# STM32H7RSxx register map
File version: 0.2
CPU: CM7 r0p1, little endian, MPU, FPU, 4 interrupt priority bits
Registers are 32-bit, read-write, reset 0x0 unless marked. A register's access mark holds for its fields unless they carry their own. Offsets are from the block's base; [hi:lo] are bit positions; {n}, {i} and the like mark numbered series; 'fields as' and 'values as' point back to an identical list; <NAME> marks a mode.

## ETH (part 1 of 4) — Ethernet register block
Base 0x40028000
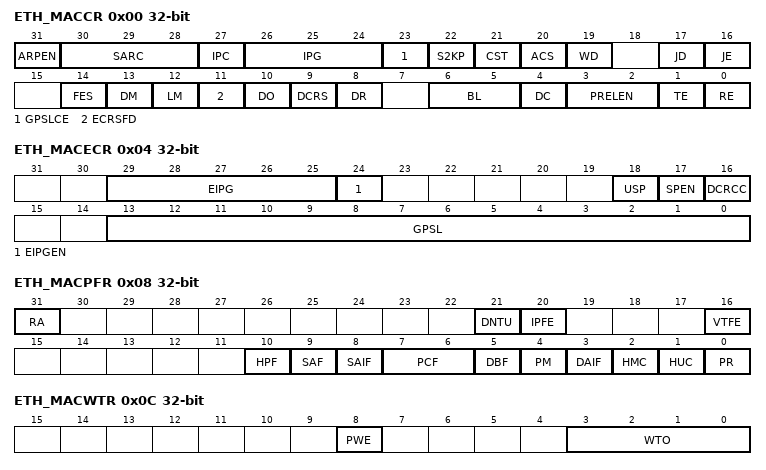
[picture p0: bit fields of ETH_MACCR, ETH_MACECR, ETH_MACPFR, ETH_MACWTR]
0x00 ETH_MACCR — Operating mode configuration register
  [31] ARPEN — ARP Offload Enable When this bit is set, the MAC can recognize an incoming ARP request packet and schedules the ARP packet for transmission. It forwards the ARP packet to the application and also indicate the events in the RxStatus. When this bit is reset, the MAC receiver does not recognize any ARP packet and indicates them as Type frame in the RxStatus.
  [30:28] SARC — Source Address Insertion or Replacement Control This field controls the source address insertion or replacement for all transmitted packets. Bit 30 specifies which MAC Address register (0 or 1) is used for source address insertion or replacement based on the values of Bits[29:28]: Others: Reserved, must not be used. Note: Changes to this field take effect only on the start of a packet. If you write to this register field when a packet is being transmitted, only the subsequent packet can use the updated value, that is, the current packet does not use the updated value.
    2=the MAC inserts the content of the MAC Address 0 registers (MAC Address 0 high register (ETH_MACA0HR) and MAC Address x low register (ETH_MACAxLR)) in the SA field of all transmitted packets; 3=the MAC replaces the content of the MAC Address 0 registers (MAC Address 0 high register (ETH_MACA0HR) and MAC Address x low register (ETH_MACAxLR)) in the SA field of all transmitted packets; 6=the MAC inserts the content of the MAC Address 1 registers (MAC Address x high register (ETH_MACAxHR) and MAC Address x low register (ETH_MACAxLR)) in the SA field of all transmitted packets; 7=the MAC replaces the content of the MAC Address 1 registers (MAC Address x high register (ETH_MACAxHR) and MAC Address x low register (ETH_MACAxLR)) in the SA field of all transmitted packets
  [27] IPC — Checksum Offload When set, this bit enables the IPv4 header checksum checking and IPv4 or IPv6 TCP, UDP, or ICMP payload checksum checking. When this bit is reset, the COE function in the receiver is disabled. The Layer 3 and Layer 4 Packet Filter feature automatically selects the IPC Full Checksum Offload Engine on the Receive side. When this feature is enabled, you must set the IPC bit.
  [26:24] IPG — Inter-Packet Gap These bits control the minimum IPG between packets during transmission. ... This range of minimum IPG is valid in Full-duplex mode. In the Half-duplex mode, the minimum IPG can be configured only for 64-bit times (IPG = 100). Lower values are not considered. When a JAM pattern is being transmitted because of backpressure activation, the MAC does not consider the minimum IPG. The above function (IPG less than 96 bit times) is valid only when EIPGEN bit in ETH_MACECR register is reset. When EIPGEN is set, then the minimum IPG (greater than 96 bit times) is controlled as per the description given in EIPG field in ETH_MACECR register.
    0=96 bit times; 1=88 bit times; 2=80 bit times; 7=40 bit times
  [23] GPSLCE — Giant Packet Size Limit Control Enable When this bit is set, the MAC considers the value in GPSL field in ETH_MACECR register to declare a received packet as Giant packet. This field must be programmed to more than 1,518 bytes. Otherwise, the MAC considers 1,518 bytes as giant packet limit. When this bit is reset, the MAC considers a received packet as Giant packet when its size is greater than 1,518 bytes (1522 bytes for tagged packet). The watchdog timeout limit, Jumbo Packet Enable and 2K Packet Enable have higher precedence over this bit, that is the MAC considers a received packet as Giant packet when its size is greater than 9,018 bytes (9,022 bytes for tagged packet) with Jumbo Packet Enabled and greater than 2,000 bytes with 2K Packet Enabled. The watchdog timeout, if enabled, terminates the received packet when watchdog limit is reached. Therefore, the programmed giant packet limit should be less than the watchdog limit to get the giant packet status.
  [22] S2KP — IEEE 802.3as Support for 2K Packets When this bit is set, the MAC considers all packets with up to 2,000 bytes length as normal packets. When the JE bit is not set, the MAC considers all received packets of size more than 2K bytes as Giant packets. When this bit is reset and the JE bit is not set, the MAC considers all received packets of size more than 1,518 bytes (1,522 bytes for tagged) as giant packets. For more information about how the setting of this bit and the JE bit impact the Giant packet status, see Table 563: Giant Packet Status based on S2KP and JE Bits. Note: When the JE bit is set, setting this bit has no effect on the giant packet status.
  [21] CST — CRC stripping for Type packets When this bit is set, the last four bytes (FCS) of all packets of Ether type (type field greater than 1,536) are stripped and dropped before forwarding the packet to the application. This function is not valid when the IP Checksum Engine (Type 1) is enabled in the MAC receiver. This function is valid when Type 2 Checksum Offload Engine is enabled. Note: For information about how the settings of the ACS bit and this bit impact the packet length, see Table 564: Packet Length based on the CST and ACS bits.
  [20] ACS — Automatic Pad or CRC Stripping When this bit is set, the MAC strips the Pad or FCS field on the incoming packets only if the value of the length field is less than 1,536 bytes. All received packets with length field greater than or equal to 1,536 bytes are passed to the application without stripping the Pad or FCS field. When this bit is reset, the MAC passes all incoming packets to the application, without any modification. Note: For information about how the settings of CST bit and this bit impact the packet length, see Table 564: Packet Length based on the CST and ACS bits.
  [19] WD — Watchdog Disable When this bit is set, the MAC disables the watchdog timer on the receiver. The MAC can receive packets of up to 16,383 bytes. When this bit is reset, the MAC does not allow more than 2,048 bytes (10,240 if JE is set high) of the packet being received. The MAC cuts off any bytes received after 2,048 bytes.
  [17] JD — Jabber Disable When this bit is set, the MAC disables the jabber timer on the transmitter. The MAC can transfer packets of up to 16,383 bytes. When this bit is reset, if the application sends more than 2,048 bytes of data (10,240 if JE is set high) during transmission, the MAC does not send rest of the bytes in that packet.
  [16] JE — Jumbo Packet Enable When this bit is set, the MAC allows jumbo packets of 9,018 bytes (9,022 bytes for VLAN tagged packets) without reporting a giant packet error in the Rx packet status. For more information about how the setting of this bit and the JE bit impact the Giant packet status, see Table 563: Giant Packet Status based on S2KP and JE Bits.
  [14] FES — MAC Speed This bit selects the speed in the 10/100 Mbps mode:
    0=10 Mbps; 1=100 Mbps
  [13] DM — Duplex Mode When this bit is set, the MAC operates in the Full-duplex mode in which it can transmit and receive simultaneously.
  [12] LM — Loopback Mode When this bit is set, the MAC operates in the loopback mode at MII. The MII Rx clock input (eth_mii_rx_clk) is required for the loopback to work properly. This is because the Tx clock is not internally looped back.
  [11] ECRSFD — Enable Carrier Sense Before Transmission in Full-duplex mode When this bit is set, the MAC transmitter checks the CRS signal before packet transmission in the Full-duplex mode. The MAC starts the transmission only when the CRS signal is low. When this bit is reset, the MAC transmitter ignores the status of the CRS signal.
  [10] DO — Disable Receive Own When this bit is set, the MAC disables the reception of packets when the ETH_TX_EN is asserted in the Half-duplex mode. When this bit is reset, the MAC receives all packets given by the PHY. This bit is not applicable in the Full-duplex mode. This bit is reserved and read-only (RO) with default value in the Full-duplex-only configurations.
  [9] DCRS — Disable Carrier Sense During Transmission When this bit is set, the MAC transmitter ignores the MII CRS signal during packet transmission in the Half-duplex mode. As a result, no errors are generated because of Loss of Carrier or No Carrier during transmission. When this bit is reset, the MAC transmitter generates errors because of Carrier Sense. The MAC can even abort the transmission.
  [8] DR — Disable Retry When this bit is set, the MAC attempts only one transmission. When a collision occurs on the MII interface, the MAC ignores the current packet transmission and reports a Packet Abort with excessive collision error in the Tx packet status. When this bit is reset, the MAC retries based on the settings of the BL field. This bit is applicable only in the Half-duplex mode.
  [6:5] BL — Back-Off Limit The back-off limit determines the random integer number (r) of slot time delays (512 bit times for 10/100 Mbps) for which the MAC waits before rescheduling a transmission attempt during retries after a collision: where n = retransmission attempt The random integer r takes the value in the range 0 <= r < 2^k. This bit is applicable only in the Half-duplex mode.
    0=k= min (n, 10); 1=k = min (n, 8); 2=k = min (n, 4); 3=k = min (n, 1)
  [4] DC — Deferral Check When this bit is set, the deferral check function is enabled in the MAC. The MAC issues a Packet Abort status, along with the excessive deferral error bit set in the Tx packet status, when the Tx state machine is deferred for more than 24,288 bit times in 10 or 100 Mbps mode. Deferral begins when the transmitter is ready to transmit, but it is prevented because of an active carrier sense signal (CRS) on MII. The defer time is not cumulative. For example, if the transmitter defers for 10,000 bit times because the CRS signal is active and the CRS signal becomes inactive, the transmitter transmits and collision happens. Because of collision, the transmitter needs to back off and then defer again after back off completion. In such a scenario, the deferral timer is reset to 0, and it is restarted. When this bit is reset, the deferral check function is disabled and the MAC defers until the CRS signal goes inactive. This bit is applicable only in the Half-duplex mode.
  [3:2] PRELEN — Preamble Length for Transmit packets These bits control the number of preamble bytes that are added to the beginning of every Tx packet. The preamble reduction occurs only when the MAC is operating in the Full-duplex mode.
    0=7 bytes of preamble; 1=5 bytes of preamble; 2=3 bytes of preamble; 3=Reserved, must not be used
  [1] TE — Transmitter Enable When this bit is set, the Tx state machine of the MAC is enabled for transmission on the MII interface. When this bit is reset, the MAC Tx state machine is disabled after it completes the transmission of the current packet. The Tx state machine does not transmit any more packets.
  [0] RE — Receiver Enable When this bit is set, the Rx state machine of the MAC is enabled for receiving packets from the MII interface. When this bit is reset, the MAC Rx state machine is disabled after it completes the reception of the current packet. The Rx state machine does not receive any more packets from the MII interface.
0x04 ETH_MACECR — Extended operating mode configuration register
  [29:25] EIPG — Extended Inter-Packet Gap The value in this field is applicable when the EIPGEN bit is set. This field (as Most Significant bits) along with IPG field in Operating mode configuration register (ETH_MACCR), gives the minimum IPG greater than 96 bit times in steps of 8 bit times. For example: EIPG = 0 and IPG = 0 give 104 bit times EIPG = 0 and IPG = 1 give 112 bit times EIPG = 0 and IPG = 2 give 120 bit times .. EIPG = 7 and IPG = 31 give 2144 bit times
  [24] EIPGEN — Extended Inter-Packet Gap Enable When this bit is set, the MAC interprets EIPG field and IPG field in Operating mode configuration register (ETH_MACCR) together as minimum IPG greater than 96 bit times in steps of 8 bit times. When this bit is reset, the MAC ignores EIPG field and interprets IPG field in Operating mode configuration register (ETH_MACCR) as minimum IPG less than or equal to 96 bit times in steps of 8 bit times. Note: The extended Inter-Packet Gap feature must be enabled when operating in Full-duplex mode only. There may be undesirable effects on back-pressure function and frame transmission if it is enabled in Half-duplex mode.
  [18] USP — Unicast Slow Protocol Packet Detect When this bit is set, the MAC detects the Slow Protocol packets with unicast address of the station specified in the MAC Address 0 high register (ETH_MACA0HR) and MAC Address 0 low register MAC Address x low register (ETH_MACAxLR). The MAC also detects the Slow Protocol packets with the Slow Protocols multicast address (01-80-C2-00-00-02). When this bit is reset, the MAC detects only Slow Protocol packets with the Slow Protocol multicast address specified in the IEEE 802.3-2008, Section 5.
  [17] SPEN — Slow Protocol Detection Enable When this bit is set, MAC processes the Slow Protocol packets (Ether Type 0x8809) and provides the Rx status. The MAC discards the Slow Protocol packets with invalid subtypes. When this bit is reset, the MAC forwards all error-free Slow Protocol packets to the application. The MAC considers such packets as normal Type packets.
  [16] DCRCC — Disable CRC Checking for Received Packets When this bit is set, the MAC receiver does not check the CRC field in the received packets. When this bit is reset, the MAC receiver always checks the CRC field in the received packets.
  [13:0] GPSL — Giant Packet Size Limit If the received packet size is greater than the value programmed in this field in units of bytes, the MAC declares the received packet as Giant packet. The value programmed in this field must be greater than or equal to 1,518 bytes. Any other programmed value is considered as 1,518 bytes. For VLAN tagged packets, the MAC adds 4 bytes to the programmed value. For double VLAN tagged packets, the MAC adds 8 bytes to the programmed value. The value in this field is applicable when the GPSLCE bit is set in ETH_MACCR register.
0x08 ETH_MACPFR — Packet filtering control register
  [31] RA — Receive All When this bit is set, the MAC Receiver module passes all received packets to the application, irrespective of whether they pass the address filter or not. The result of the SA or DA filtering is updated (pass or fail) in the corresponding bit in the Rx Status Word. When this bit is reset, the Receiver module passes only those packets to the application that pass the SA or DA address filter.
  [21] DNTU — Drop Non-TCP/UDP over IP Packets When this bit is set, the MAC drops the non-TCP or UDP over IP packets. The MAC forward only those packets that are processed by the Layer 4 filter. When this bit is reset, the MAC forwards all non-TCP or UDP over IP packets.
  [20] IPFE — Layer 3 and Layer 4 Filter Enable When this bit is set, the MAC drops packets that do not match the enabled Layer 3 and Layer 4 filters. If Layer 3 or Layer 4 filters are not enabled for matching, this bit does not have any effect. When this bit is reset, the MAC forwards all packets irrespective of the match status of the Layer 3 and Layer 4 fields.
  [16] VTFE — VLAN Tag Filter Enable When this bit is set, the MAC drops the VLAN tagged packets that do not match the VLAN Tag. When this bit is reset, the MAC forwards all packets irrespective of the match status of the VLAN Tag.
  [10] HPF — Hash or Perfect Filter When this bit is set, the address filter passes a packet if it matches either the perfect filtering or Hash filtering as set by the HMC or HUC bit. When this bit is reset and the HUC or HMC bit is set, the packet is passed only if it matches the Hash filter.
  [9] SAF — Source Address Filter Enable When this bit is set, the MAC compares the SA field of the received packets with the values programmed in the enabled SA registers. If the comparison fails, the MAC drops the packet. When this bit is reset, the MAC forwards the received packet to the application with updated SAF bit of the Rx Status depending on the SA address comparison. Note: According to the IEEE specification, Bit 47 of the SA is reserved. However, the MAC compares all 48 bits. The software driver should take this into consideration while programming the MAC address registers for SA.
  [8] SAIF — SA Inverse Filtering When this bit is set, the Address Check block operates in the inverse filtering mode for SA address comparison. If the SA of a packet matches the values programmed in the SA registers, it is marked as failing the SA Address filter. When this bit is reset, if the SA of a packet does not match the values programmed in the SA registers, it is marked as failing the SA Address filter.
  [7:6] PCF — Pass Control Packets These bits control the forwarding of all control packets (including unicast and multicast Pause packets).
    0=The MAC filters all control packets from reaching the application; 1=The MAC forwards all control packets except Pause packets to the application even if they fail the Address filter; 2=The MAC forwards all control packets to the application even if they fail the Address filter; 3=The MAC forwards the control packets that pass the Address filter
  [5] DBF — Disable Broadcast Packets When this bit is set, the AFM module blocks all incoming broadcast packets. In addition, it overrides all other filter settings. When this bit is reset, the AFM module passes all received broadcast packets.
  [4] PM — Pass All Multicast When this bit is set, it indicates that all received packets with a multicast destination address (first bit in the destination address field is '1') are passed. When this bit is reset, filtering of multicast packet depends on HMC bit.
  [3] DAIF — DA Inverse Filtering When this bit is set, the Address Check block operates in inverse filtering mode for the DA address comparison for both unicast and multicast packets. When this bit is reset, normal filtering of packets is performed.
  [2] HMC — Hash Multicast When this bit is set, the MAC performs the destination address filtering of received multicast packets according to the Hash table. When this bit is reset, the MAC performs the perfect destination address filtering for multicast packets, that is, it compares the DA field with the values programmed in DA registers.
  [1] HUC — Hash Unicast When this bit is set, the MAC performs the destination address filtering of unicast packets according to the Hash table. When this bit is reset, the MAC performs a perfect destination address filtering for unicast packets, that is, it compares the DA field with the values programmed in DA registers.
  [0] PR — Promiscuous Mode When this bit is set, the Address Filtering module passes all incoming packets irrespective of the destination or source address. The SA or DA Filter Fails status bits of the Rx Status Word are always cleared when PR is set.
0x0C ETH_MACWTR — Watchdog timeout register
  [8] PWE — Programmable Watchdog Enable When this bit is set and the WD bit of the Operating mode configuration register (ETH_MACCR) register is reset, the WTO field is used as watchdog timeout for a received packet. When this bit is cleared, the watchdog timeout for a received packet is controlled by setting of WD and JE bits in Operating mode configuration register (ETH_MACCR) register.
  [3:0] WTO — Watchdog Timeout When the PWE bit is set and the WD bit of the Operating mode configuration register (ETH_MACCR) register is reset, this field is used as watchdog timeout for a received packet. If the length of a received packet exceeds the value of this field, such packet is terminated and declared as an error packet. Encoding is as follows: .. Note: When the PWE bit is set, the value in this field should be more than 1,522 (0x05F2). Otherwise, the IEEE 802.3-specified valid tagged packets are declared as error packets and then dropped.
    {v}={v+2} Kbytes (v=0..3); 12=14 Kbytes; 13=15 Kbytes; 14=16383 Bytes; 15=Reserved, must not be used
0x10 ETH_MACHT0R — Hash Table 0 register
  [31:0] HT31T0 — MAC Hash Table First 32 Bits This field contains the first 32 Bits [31:0] of the Hash table.
0x14 ETH_MACHT1R — Hash Table 1 register
  [31:0] HT63T32 — MAC Hash Table Second 32 Bits This field contains the second 32 Bits [63:32] of the Hash table.
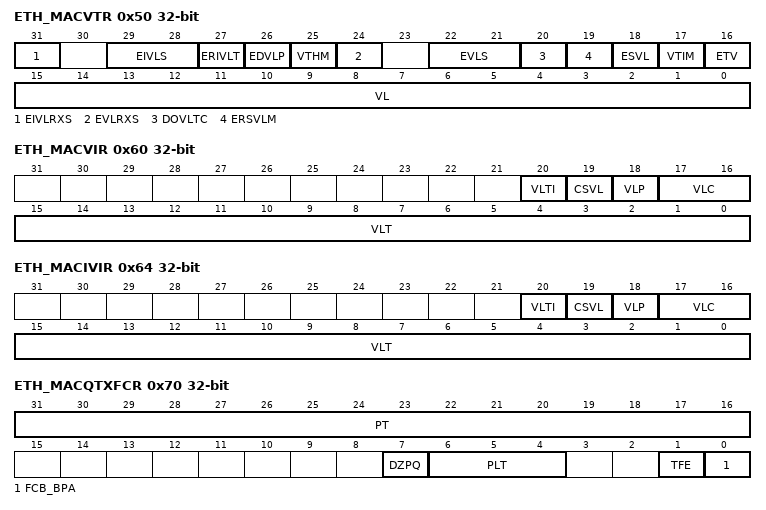
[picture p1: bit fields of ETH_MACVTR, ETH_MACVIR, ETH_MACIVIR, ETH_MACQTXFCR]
0x50 ETH_MACVTR — VLAN tag register
  [31] EIVLRXS — Enable Inner VLAN Tag in Rx Status When this bit is set, the MAC provides the inner VLAN Tag in the Rx status. When this bit is reset, the MAC does not provide the inner VLAN Tag in Rx status.
  [29:28] EIVLS — Enable Inner VLAN Tag Stripping on Receive This field indicates the stripping operation on inner VLAN Tag in received packet:
    0=Do not strip; 1=Strip if VLAN filter passes; 2=Strip if VLAN filter fails; 3=Always strip
  [27] ERIVLT — Enable Inner VLAN Tag When this bit and the EDVLP field are set, the MAC receiver enables operation on the inner VLAN Tag (if present). When this bit is reset, the MAC receiver enables operation on the outer VLAN Tag (if present). The ERSVLM bit determines which VLAN type is enabled for filtering or matching.The ERSVLM bit and DOVLTC bit determines which VLAN type is enabled for filtering.
  [26] EDVLP — Enable Double VLAN Processing When this bit is set, the MAC enables processing of up to two VLAN Tags on Tx and Rx (if present). When this bit is reset, the MAC enables processing of up to one VLAN Tag on Tx and Rx (if present).
  [25] VTHM — VLAN Tag Hash Table Match Enable When this bit is set, the most significant four bits of CRC of VLAN Tag are used to index the content of the ETH_MACVLANHTR register. A value of 1 in the VLAN Hash Table register, corresponding to the index, indicates that the packet matched the VLAN Hash table. When the ETV bit is set, the CRC of the 12-bit VLAN Identifier (VID) is used for comparison. When the ETV bit is reset, the CRC of the 16-bit VLAN tag is used for comparison. When this bit is reset, the VLAN Hash Match operation is not performed.
  [24] EVLRXS — Enable VLAN Tag in Rx status When this bit is set, MAC provides the outer VLAN Tag in the Rx status. When this bit is reset, the MAC does not provide the outer VLAN Tag in Rx status.
  [22:21] EVLS — Enable VLAN Tag Stripping on Receive This field indicates the stripping operation on the outer VLAN Tag in received packet:
    values as EIVLS
  [20] DOVLTC — Disable VLAN Type Check When this bit is set, the MAC does not check whether the VLAN Tag specified by the ERIVLT bit is of type S-VLAN or C-VLAN. When this bit is reset, the MAC filters or matches the VLAN Tag specified by the ERIVLT bit only when VLAN Tag type is similar to the one specified by the ERSVLM bit.
  [19] ERSVLM — Enable Receive S-VLAN Match When this bit is set, the MAC receiver enables filtering or matching for S-VLAN (Type = 0x88A8) packets. When this bit is reset, the MAC receiver enables filtering or matching for C-VLAN (Type = 0x8100) packets. The ERIVLT bit determines the VLAN tag position considered for filtering or matching.
  [18] ESVL — Enable S-VLAN When this bit is set, the MAC transmitter and receiver consider the S-VLAN packets (Type = 0x88A8) as valid VLAN tagged packets.
  [17] VTIM — VLAN Tag Inverse Match Enable When this bit is set, this bit enables the VLAN Tag inverse matching. The packets without matching VLAN Tag are marked as matched. When reset, this bit enables the VLAN Tag perfect matching. The packets with matched VLAN Tag are marked as matched.
  [16] ETV — Enable 12-Bit VLAN Tag Comparison When this bit is set, a 12-bit VLAN identifier is used for comparing and filtering instead of the complete 16-bit VLAN tag. Bits[11:0] of VLAN tag are compared with the corresponding field in the received VLAN-tagged packet. Similarly, when enabled, only 12 bits of the VLAN tag in the received packet are used for Hash-based VLAN filtering. When this bit is reset, all 16 bits of the 15th and 16th bytes of the received VLAN packet are used for comparison and VLAN Hash filtering.
  [15:0] VL — VLAN Tag Identifier for Receive Packets This field contains the 802.1Q VLAN tag to identify the VLAN packets. This VLAN tag identifier is compared to the 15th and 16th bytes of the packets being received for VLAN packets. The following list describes the bits of this field: Bits[15:13]: User Priority Bit 12: Canonical Format Indicator (CFI) or Drop Eligible Indicator (DEI) Bits[11:0]: VLAN Identifier (VID) field of VLAN tag When the ETV bit is set, only the VID is used for comparison. If this field ([11:0] if ETV is set) is all zeros, the MAC does not check the 15th and 16th bytes for VLAN tag comparison and declares all packets with Type field value of 0x8100 or 0x88a8 as VLAN packets.
0x58 ETH_MACVHTR — VLAN Hash table register
  [15:0] VLHT — VLAN Hash Table This field contains the 16-bit VLAN Hash Table.
0x60 ETH_MACVIR — VLAN inclusion register
  [20] VLTI — VLAN Tag Input When this bit is set, it indicates that the VLAN tag to be inserted or replaced in Tx packet should be taken from the Tx descriptor.
  [19] CSVL — C-VLAN or S-VLAN When this bit is set, S-VLAN type (0x88A8) is inserted or replaced in the 13th and 14th bytes of transmitted packets. When this bit is reset, C-VLAN type (0x8100) is inserted or replaced in the 13th and 14th bytes of transmitted packets.
    0=C-LAN; 1=S-LAN
  [18] VLP — VLAN Priority Control When this bit is set, the control bits[17:16] are used for VLAN deletion, insertion, or replacement. When this bit is reset, bits[17:16] are ignored.
  [17:16] VLC — VLAN Tag Control in Transmit Packets Note: Changes to this field take effect only on the start of a packet. If you write this register field when a packet is being transmitted, only the subsequent packet can use the updated value, that is, the current packet does not use the updated value.
    0=No VLAN tag deletion, insertion, or replacement; 1=VLAN tag deletion. The MAC removes the VLAN type (bytes 13 and 14) and VLAN tag (bytes 15 and 16) of all transmitted packets with VLAN tags.; 2=VLAN tag insertion. The MAC inserts VLT in bytes 15 and 16 of the packet after inserting the Type value (0x8100 or 0x88a8) in bytes 13 and 14. This operation is performed on all transmitted packets, irrespective of whether they already have a VLAN tag.; 3=VLAN tag replacement. The MAC replaces VLT in bytes 15 and 16 of all VLAN-type transmitted packets (Bytes 13 and 14 are 0x8100 or 0x88a8).
  [15:0] VLT — VLAN Tag for Transmit Packets This field contains the value of the VLAN tag to be inserted or replaced. The value must only be changed when the transmit lines are inactive or during the initialization phase. The following list describes the bits of this field: Bits[15:13]: User Priority Bit 12: Canonical Format Indicator (CFI) or Drop Eligible Indicator (DEI) Bits[11:0]: VLAN Identifier (VID) field of VLAN tag
0x64 ETH_MACIVIR — Inner VLAN inclusion register
  [20] VLTI — VLAN Tag Input When this bit is set, it indicates that the VLAN tag to be inserted or replaced in Tx packet should be taken from the Tx descriptor
  [19] CSVL — C-VLAN or S-VLAN When this bit is set, S-VLAN type (0x88A8) is inserted or replaced in the 13th and 14th bytes of transmitted packets. When this bit is reset, C-VLAN type (0x8100) is inserted or replaced in the 13th and 14th bytes of transmitted packets.
    0=C-LAN; 1=S-LAN
  [18] VLP — VLAN Priority Control When this bit is set, the VLC field is used for VLAN deletion, insertion, or replacement. When this bit is reset, the VLC field is ignored.
  [17:16] VLC — VLAN Tag Control in Transmit Packets The MAC removes the VLAN type (bytes 17 and 18) and VLAN tag (bytes 19 and 20) of all transmitted packets with VLAN tags. The MAC inserts VLT in bytes 19 and 20 of the packet after inserting the Type value (0x8100 or 0x88a8) in bytes 17 and 18. This operation is performed on all transmitted packets, irrespective of whether they already have a VLAN tag. The MAC replaces VLT in bytes 19 and 20 of all VLAN-type transmitted packets (Bytes 17 and 18 are 0x8100 or 0x88a8). Note: Changes to this field take effect only on the start of a packet. If you write to this register field when a packet is being transmitted, only the subsequent packet can use the updated value, that is, the current packet does not use the updated value.
    0=No VLAN tag deletion, insertion, or replacement; 1=VLAN tag deletion; 2=VLAN tag insertion; 3=VLAN tag replacement
  [15:0] VLT — VLAN Tag for Transmit Packets This field contains the value of the VLAN tag to be inserted or replaced. The value must only be changed when the transmit lines are inactive or during the initialization phase. The following list describes the bits of this field: Bits[15:13]: User Priority Bit 12: Canonical Format Indicator (CFI) or Drop Eligible Indicator (DEI) Bits[11:0]: VLAN Identifier (VID) field of VLAN tag
0x70 ETH_MACQTXFCR — Tx Queue flow control register
  [31:16] PT — Pause Time This field holds the value to be used in the Pause Time field in the Tx control packet. I
  [7] DZPQ — Disable Zero-Quanta Pause When this bit is set, it disables the automatic generation of the zero-quanta Pause packets. When this bit is reset, normal operation with automatic zero-quanta Pause packet generation is enabled.
  [6:4] PLT — Pause Low Threshold This field configures the threshold of the Pause timer at which the input flow is checked for automatic retransmission of the Pause packet. The threshold values should be always less than the Pause Time configured in Bits[31:16]. For example, if PT = 100H (256 slot times), and PLT = 001, a second Pause packet is automatically transmitted at 228 (256-28) slot times after the first Pause packet is transmitted. The following list provides the threshold values for different values: 110 to 111: Reserved, must not be used The slot time is defined as the time taken to transmit 512 bits (64 bytes) on the MII interface. This (approximate) computation is based on the packet size (64, 1518, 2000, 9018, 16384, or 32768) + 2 Pause Packet Size + IPG in Slot Times.
    0=Pause Time minus 4 Slot Times (PT -4 slot times); 1=Pause Time minus 28 Slot Times (PT -28 slot times); 2=Pause Time minus 36 Slot Times (PT -36 slot times); 3=Pause Time minus 144 Slot Times (PT -144 slot times); 4=Pause Time minus 256 Slot Times (PT -256 slot times); 5=Pause Time minus 512 Slot Times (PT -512 slot times)
  [1] TFE — Transmit Flow Control Enable Full-duplex mode: when this bit is set, the MAC enables the flow control operation to Tx Pause packets. When this bit is reset, the flow control operation in the MAC is disabled, and the MAC does not transmit any Pause packets. Half-duplex mode: when this bit is set, the MAC enables the backpressure operation. When this bit is reset, the backpressure feature is disabled.
  [0] FCB_BPA — Flow Control Busy or Backpressure Activate This bit initiates a Pause packet in the Full-duplex mode and activates the backpressure function in the Half-duplex mode if the TFE bit is set. Full-Duplex mode: this bit should be read as 0 before writing to this register. To initiate a Pause packet, the application must set this bit to 1. During Control packet transfer, this bit continues to be set to indicate that a packet transmission is in progress. When Pause packet transmission is complete, the MAC resets this bit to 0. You should not write to this register until this bit is cleared. Half-duplex mode: When this bit is set (and TFE bit is set) in the Half-duplex mode, the MAC asserts the backpressure. During backpressure, when the MAC receives a new packet, the transmitter starts sending a JAM pattern resulting in a collision. When the MAC is configured for the Full-duplex mode, the BPA is automatically disabled.
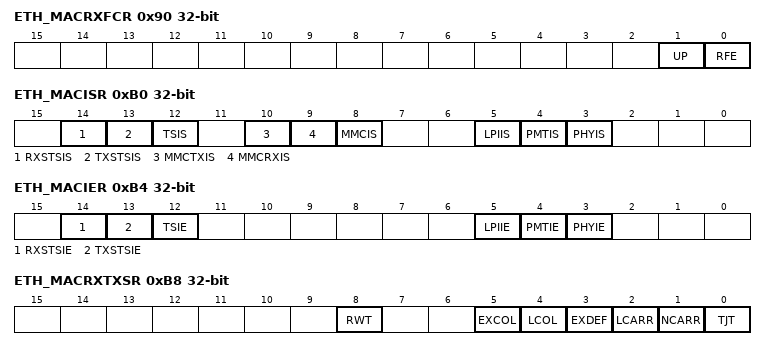
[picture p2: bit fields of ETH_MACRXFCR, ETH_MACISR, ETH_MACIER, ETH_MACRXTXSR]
0x90 ETH_MACRXFCR — Rx flow control register
  [1] UP — Unicast Pause Packet Detect A pause packet is processed when it has the unique multicast address specified in the IEEE 802.3. When this bit is set, the MAC can also detect Pause packets with unicast address of the station. This unicast address should be as specified in MAC Address 0 high register (ETH_MACA0HR) and MAC Address 0 low register MAC Address x low register (ETH_MACAxLR). When this bit is reset, the MAC only detects Pause packets with unique multicast address. Note: The MAC does not process a Pause packet if the multicast address is different from the unique multicast address. This is also applicable to the received PFC packet when the Priority Flow Control (PFC) is enabled. The unique multicast address (0x01_80_C2_00_00_01) is as specified in IEEE 802.1 Qbb-2011.
  [0] RFE — Receive Flow Control Enable When this bit is set and the MAC is operating in Full-duplex mode, the MAC decodes the received Pause packet and disables its transmitter for a specified (Pause) time. When this bit is reset or the MAC is operating in Half-duplex mode, the decode function of the Pause packet is disabled. When PFC is enabled, flow control is enabled for PFC packets. The MAC decodes the received PFC packet and disables the Transmit queue, with matching priorities, for a duration of received Pause time.
0xB0 ETH_MACISR access per field — Interrupt status register
  [14] RXSTSIS rw read-clears — Receive Status Interrupt This bit indicates the status of received packets. This bit is set when the RWT bit is set in the Rx Tx status register (ETH_MACRXTXSR). This bit is cleared when the corresponding interrupt source bit is read (or corresponding interrupt source bit is written to 1 when RCWE bit of CSR software control register (ETH_MACCSRSWCR) is set) in the ETH_MACISR register.
  [13] TXSTSIS rw read-clears — Transmit Status Interrupt This bit indicates the status of transmitted packets. This bit is set when any of the following bits is set in the Rx Tx status register (ETH_MACRXTXSR): Excessive Collision (EXCOL) Late Collision (LCOL) Excessive Deferral (EXDEF) Loss of Carrier (LCARR) No Carrier (NCARR) Jabber Timeout (TJT) This bit is cleared when the corresponding interrupt source bit is read (or corresponding interrupt source bit is written to 1 when RCWE bit of CSR software control register (ETH_MACCSRSWCR) is set) in the ETH_MACISR register.
  [12] TSIS rw read-clears — Timestamp Interrupt Status If the Timestamp feature is enabled, this bit is set when any of the following conditions is true: The system time value is equal to or exceeds the value specified in the Target Time High and Low registers. There is an overflow in the Seconds register. The Target Time Error occurred, that is, programmed target time already elapsed. If the Auxiliary Snapshot feature is enabled, this bit is set when the auxiliary snapshot trigger is asserted. When drop transmit status is enabled in MTL, this bit is set when the captured transmit timestamp is updated in the Tx timestamp status nanoseconds register (ETH_MACTXTSSNR) and Tx timestamp status seconds register (ETH_MACTXTSSSR) registers. When PTP offload feature is enabled, this bit is set when the captured transmit timestamp is updated in the Tx timestamp status nanoseconds register (ETH_MACTXTSSNR) and Tx timestamp status seconds register (ETH_MACTXTSSSR) registers, for PTO generated Delay Request and Pdelay request packets. This bit is cleared when the corresponding interrupt source bit is read (or corresponding interrupt source bit is written to 1 when RCWE bit of CSR software control register (ETH_MACCSRSWCR) is set) in the Timestamp status register (ETH_MACTSSR).
  [10] MMCTXIS ro — MMC Transmit Interrupt Status This bit is set high when an interrupt is generated in the MMC Tx interrupt register (ETH_MMC_TX_INTERRUPT). This bit is cleared when all bits in this interrupt register are cleared.
  [9] MMCRXIS ro — MMC Receive Interrupt Status This bit is set high when an interrupt is generated in the MMC Rx interrupt register (ETH_MMC_RX_INTERRUPT). This bit is cleared when all bits in this interrupt register are cleared.
  [8] MMCIS ro — MMC Interrupt Status This bit is set high when MMCTXIS or MMCRXIS is set high. This bit is cleared only when all these bits are low.
  [5] LPIIS ro — LPI Interrupt Status This bit is set for any LPI state entry or exit in the MAC Transmitter or Receiver. This bit is cleared when the TLPIEN bit of LPI control and status register (ETH_MACLCSR) is read.
  [4] PMTIS ro — PMT Interrupt Status This bit is set when a Magic packet or Wake-on-LAN packet is received in the power-down mode (RWKPRCVD and MGKPRCVD bits in ETH_MACPCSR register). This bit is cleared when Bits[6:5] are cleared because of a Read operation to the PMT control status register (ETH_MACPCSR).
  [3] PHYIS ro — PHY Interrupt This bit is set when rising edge is detected on the ETH_PHY_INTN input. This bit is cleared when this register is read.
0xB4 ETH_MACIER — Interrupt enable register
  [14] RXSTSIE — Receive Status Interrupt Enable When this bit is set, it enables the assertion of the interrupt signal because of the setting of RXSTSIS bit in the Interrupt status register (ETH_MACISR).
  [13] TXSTSIE — Transmit Status Interrupt Enable When this bit is set, it enables the assertion of the interrupt signal because of the setting of TXSTSIS bit in the Interrupt status register (ETH_MACISR).
  [12] TSIE — Timestamp Interrupt Enable When this bit is set, it enables the assertion of the interrupt signal because of the setting of TSIS bit in Interrupt status register (ETH_MACISR).
  [5] LPIIE — LPI Interrupt Enable When this bit is set, it enables the assertion of the interrupt signal because of the setting of LPIIS bit in Interrupt status register (ETH_MACISR).
  [4] PMTIE — PMT Interrupt Enable When this bit is set, it enables the assertion of the interrupt signal because of the setting of PMTIS bit in Interrupt status register (ETH_MACISR).
  [3] PHYIE — PHY Interrupt Enable When this bit is set, it enables the assertion of the interrupt signal because of the setting of PHYIS bit in Interrupt status register (ETH_MACISR).
0xB8 ETH_MACRXTXSR — Rx Tx status register
  [8] RWT read-clears — Receive Watchdog Timeout This bit is set when a packet with length greater than 2,048 bytes is received (10, 240 bytes when Jumbo Packet mode is enabled) and the WD bit is reset in the Operating mode configuration register (ETH_MACCR). This bit is set when a packet with length greater than 16,383 bytes is received and the WD bit is set in the Operating mode configuration register (ETH_MACCR). Cleared on read (or write of 1 when RCWE bit in CSR software control register (ETH_MACCSRSWCR) is set).
  [5] EXCOL read-clears — Excessive Collisions When the DTXSTS bit is set in the Operating mode Register (ETH_MTLOMR), this bit indicates that the transmission aborted after 16 successive collisions while attempting to transmit the current packet. If the DR bit is set in the Operating mode configuration register (ETH_MACCR), this bit is set after the first collision and the packet transmission is aborted. Cleared on read (or write of 1 when RCWE bit in CSR software control register (ETH_MACCSRSWCR) is set).
  [4] LCOL read-clears — Late Collision When the DTXSTS bit is set in the Operating mode Register (ETH_MTLOMR), this bit indicates that the packet transmission aborted because a collision occurred after the collision window (64 bytes including Preamble in MII mode. This bit is not valid if the Underflow error occurs. Cleared on read (or write of 1 when RCWE bit in CSR software control register (ETH_MACCSRSWCR) is set).
  [3] EXDEF read-clears — Excessive Deferral When the DTXSTS bit is set in the Operating mode Register (ETH_MTLOMR) and the DC bit is set in the Operating mode configuration register (ETH_MACCR), this bit indicates that the transmission ended because of excessive deferral of over 24,288 bit times (155,680 when Jumbo packet is enabled). Cleared on read (or write of 1 when RCWE bit in CSR software control register (ETH_MACCSRSWCR) is set).
  [2] LCARR read-clears — Loss of Carrier When the DTXSTS bit is set in the Operating mode Register (ETH_MTLOMR), this bit indicates that the loss of carrier occurred during packet transmission, that is, the ETH_CRS signal was inactive for one or more transmission clock periods during packet transmission. This bit is valid only for packets transmitted without collision. Cleared on read (or write of 1 when RCWE bit in CSR software control register (ETH_MACCSRSWCR) is set).
  [1] NCARR read-clears — No Carrier When the DTXSTS bit is set in the Operating mode Register (ETH_MTLOMR), this bit indicates that the carrier signal from the PHY is not present at the end of preamble transmission. Cleared on read (or write of 1 when RCWE bit in CSR software control register (ETH_MACCSRSWCR) is set).
  [0] TJT read-clears — Transmit Jabber Timeout This bit indicates that the Transmit Jabber Timer expired which happens when the packet size exceeds 2,048 bytes (10,240 bytes when the Jumbo packet is enabled) and JD bit is reset in the Operating mode configuration register (ETH_MACCR). This bit is set when the packet size exceeds 16,383 bytes and the JD bit is set in the Operating mode configuration register (ETH_MACCR). Cleared on read (or write of 1 when RCWE bit in CSR software control register (ETH_MACCSRSWCR) is set).
